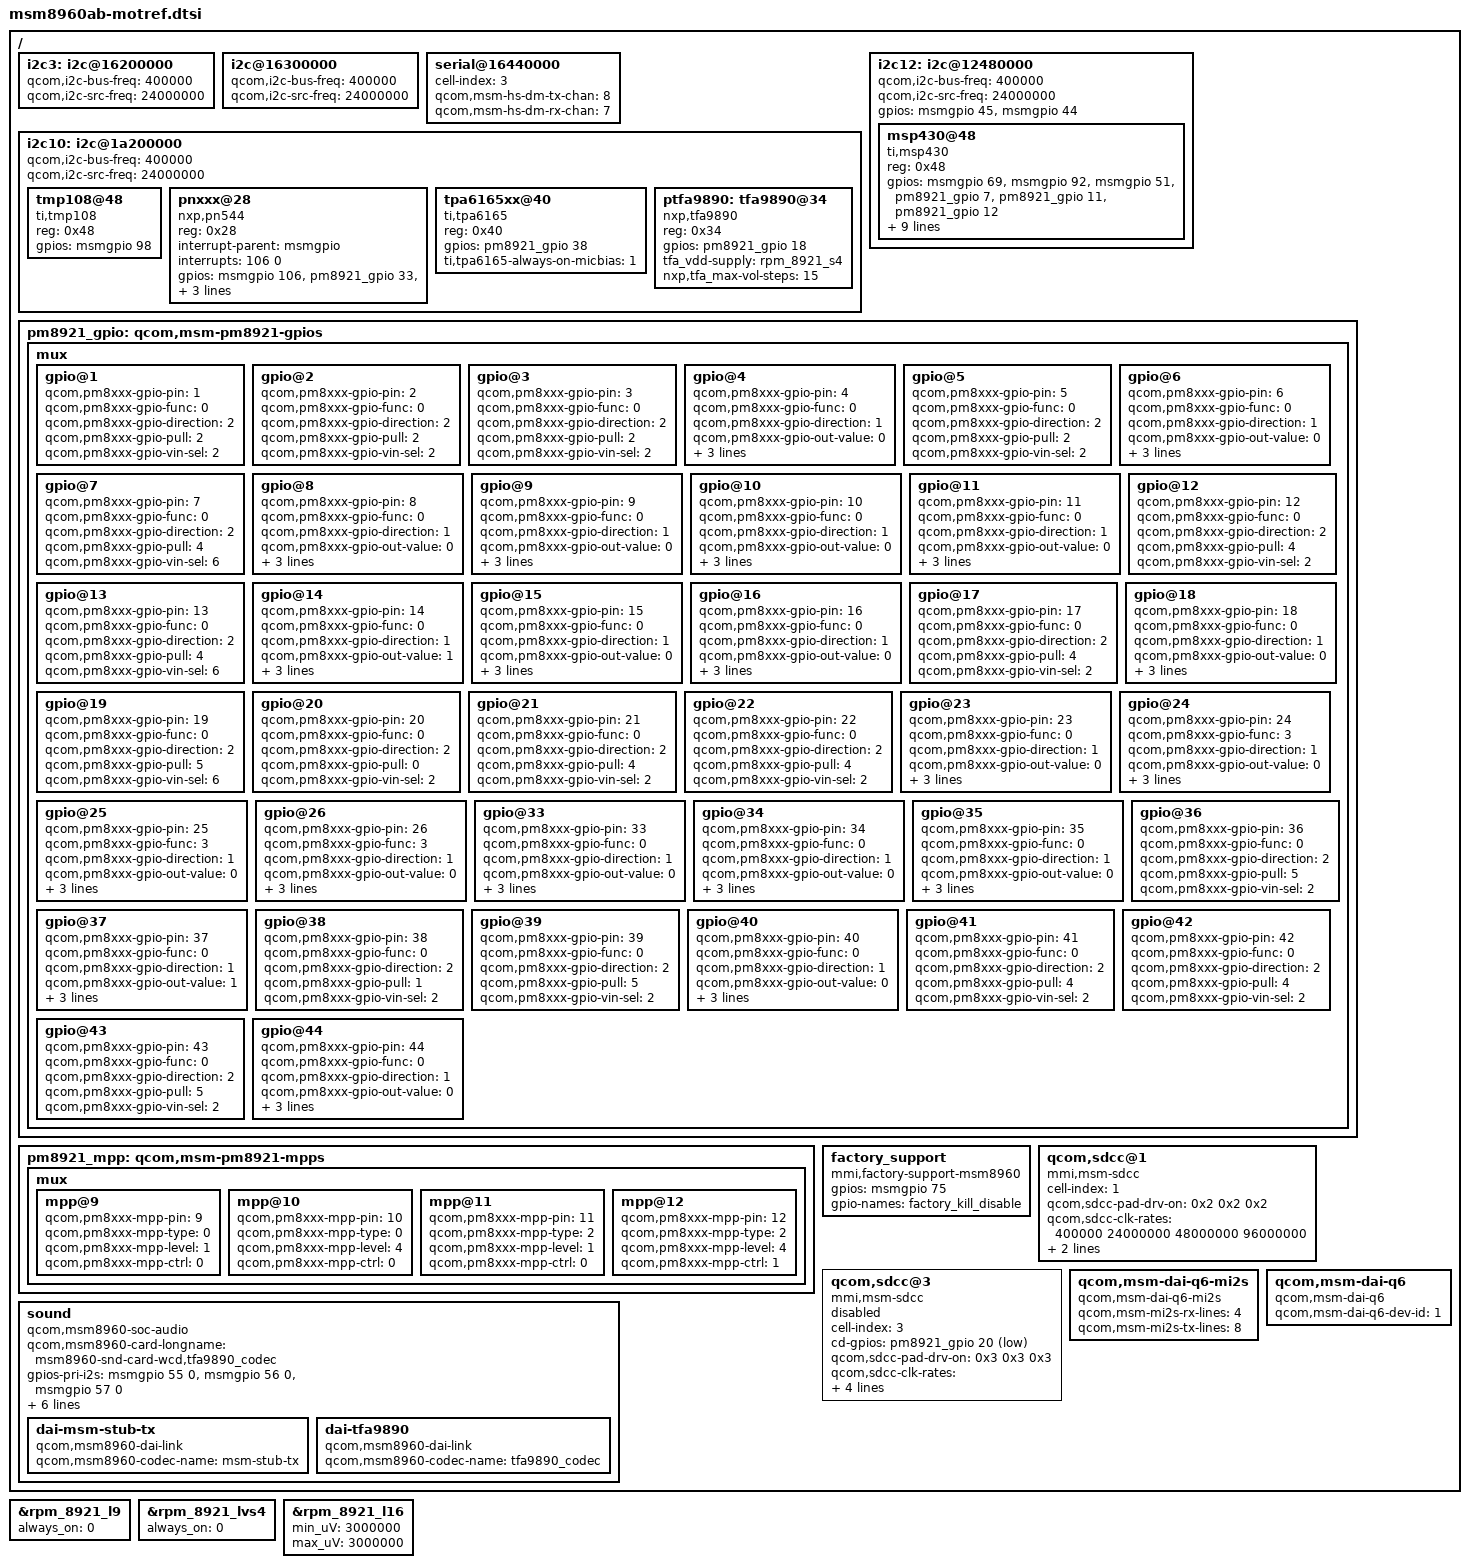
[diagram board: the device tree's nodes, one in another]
/* Common devices of all Motorola msm8960ab reference design based hardware */

/include/ "skeleton.dtsi"
/include/ "msm8960.dtsi"

/include/ "msm8960-motref-pinmux.dtsi"

&rpm_8921_l9 {
	always_on = <0>;
};

&rpm_8921_lvs4 {
	always_on = <0>;
};

&rpm_8921_l16 {
	min_uV = <3000000>;
	max_uV = <3000000>;
};


/ {
	/* GSBI3 - I2C */
	i2c3: i2c@16200000 {
		status = "okay";

		qcom,i2c-bus-freq = <400000>;
		qcom,i2c-src-freq = <24000000>;
	};

	/* GSBI4 - I2C */
	i2c@16300000 {
		status = "okay";

		qcom,i2c-bus-freq = <400000>;
		qcom,i2c-src-freq = <24000000>;
	};

	/* GSBI5 - UART */
	serial@16440000 {
		status = "okay";

		cell-index = <3>;

		qcom,msm-hs-dm-tx-chan = <8>;
		qcom,msm-hs-dm-rx-chan = <7>;
	};

	/* GSBI10 - I2C */
	i2c10: i2c@1a200000 {
		status = "okay";

		qcom,i2c-bus-freq = <400000>;
		qcom,i2c-src-freq = <24000000>;

		tmp108@48 {
			compatible = "ti,tmp108";
			reg = <0x48>;
			gpios = <&msmgpio 98 0>;
		};

		pnxxx@28 {
			compatible = "nxp,pn544";
			reg = <0x28>;
			interrupt-parent = <&msmgpio>;
			interrupts = <106 0>;
			gpios = <&msmgpio 106 0>,     /* IRQ */
				<&pm8921_gpio 33 0>,  /* VEN */
				<&pm8921_gpio 16 0>;  /* Firmware */

			nxp,pnxxx-discharge-delay = <2000>;
			nxp,pnxxx-ven-inv-polarity = <0>;
		};

		tpa6165xx@40 {
			compatible = "ti,tpa6165";
			reg = <0x40>;
			gpios = <&pm8921_gpio 38 0>;     /* IRQ */
			ti,tpa6165-always-on-micbias = <1>;
		};

		ptfa9890: tfa9890@34 {
			compatible = "nxp,tfa9890";
			reg = <0x34>;
			gpios = <&pm8921_gpio 18 0>;     /* RESET */
			tfa_vdd-supply = <&rpm_8921_s4>;
			nxp,tfa_max-vol-steps = <15>;
		};
	};

	/* GSBI12 - I2C */
	i2c12: i2c@12480000 {
		status = "okay";

		qcom,i2c-bus-freq = <400000>;
		qcom,i2c-src-freq = <24000000>;

		gpios = <&msmgpio 45 0>,            /* CLK */
			<&msmgpio 44 0>;            /* DAT */

		msp430@48 {
			compatible = "ti,msp430";
			reg = <0x48>;
			gpios = <&msmgpio 69 0>,     /* IRQ */
				<&msmgpio 92 0>,     /* RESET */
				<&msmgpio 51 0>,     /* BSLEN */
				<&pm8921_gpio 7 0>,  /* WakeIRQ */
				<&pm8921_gpio 11 0>, /* MIPI_REQ */
				<&pm8921_gpio 12 0>; /* MIPI_BUSY */
			lux_table = <5 50 100 1500 3000 8000>;
			brightness_table = <8 13 17 42 61 84 140>;
			bslen_pin_active_value = <1>;
			ct406_detect_threshold = <0x006E>;
			ct406_undetect_threshold = <0x0050>;
			ct406_recalibrate_threshold = <0x0064>;
			ct406_pulse_count = <0x04>;
			vio-supply = <&rpm_8921_lvs4>;
			vcc-supply = <&rpm_8921_l9>;
		};
	};

	pm8921_gpio: qcom,msm-pm8921-gpios {
		mux {
			status = "okay";

			/* KYPD_SNS1 */
			gpio@1 {
				qcom,pm8xxx-gpio-pin = <1>;

				/*
				 * Function    : Normal
				 * Direction   : Input
				 * Pull        : PullUp 31P5
				 * VIN Select  : S4
				 */
				qcom,pm8xxx-gpio-func = <0>;
				qcom,pm8xxx-gpio-direction = <2>;
				qcom,pm8xxx-gpio-pull = <2>;
				qcom,pm8xxx-gpio-vin-sel = <2>;
			};

			/* KYPD_SNS2 */
			gpio@2 {
				qcom,pm8xxx-gpio-pin = <2>;

				/*
				 * Function    : Normal
				 * Direction   : Input
				 * Pull        : PullUp 31P5
				 * VIN Select  : S4
				 */
				qcom,pm8xxx-gpio-func = <0>;
				qcom,pm8xxx-gpio-direction = <2>;
				qcom,pm8xxx-gpio-pull = <2>;
				qcom,pm8xxx-gpio-vin-sel = <2>;
			};

			/* KYPD_SNS3 */
			gpio@3 {
				qcom,pm8xxx-gpio-pin = <3>;

				/*
				 * Function    : Normal
				 * Direction   : Input
				 * Pull        : PullUp 31P5
				 * VIN Select  : S4
				 */
				qcom,pm8xxx-gpio-func = <0>;
				qcom,pm8xxx-gpio-direction = <2>;
				qcom,pm8xxx-gpio-pull = <2>;
				qcom,pm8xxx-gpio-vin-sel = <2>;
			};

			/* TOUCH_R_REQ */
			gpio@4 {
				qcom,pm8xxx-gpio-pin = <4>;

				/*
				 * Function    : Normal
				 * Direction   : Output
				 * Output Val  : Low
				 * Out Strngth : High
				 * Pull        : None
				 * VIN Select  : L17
				*/
				qcom,pm8xxx-gpio-func = <0>;
				qcom,pm8xxx-gpio-direction = <1>;
				qcom,pm8xxx-gpio-out-value = <0>;
				qcom,pm8xxx-gpio-out-strength = <1>;
				qcom,pm8xxx-gpio-pull = <5>;
				qcom,pm8xxx-gpio-vin-sel = <6>;
			};

			/* KYPD_SNS5 */
			gpio@5 {
				qcom,pm8xxx-gpio-pin = <5>;

				/*
				 * Function    : Normal
				 * Direction   : Input
				 * Pull        : PullUp 31P5
				 * VIN Select  : S4
				 */
				qcom,pm8xxx-gpio-func = <0>;
				qcom,pm8xxx-gpio-direction = <2>;
				qcom,pm8xxx-gpio-pull = <2>;
				qcom,pm8xxx-gpio-vin-sel = <2>;
			};

			/* CAM_F_SEL */
			gpio@6 {
				qcom,pm8xxx-gpio-pin = <6>;

				/*
				 * Function    : Normal
				 * Direction   : Output
				 * Output Val  : Low
				 * Out Strngth : High
				 * Pull        : None
				 * VIN Select  : S4
				*/
				qcom,pm8xxx-gpio-func = <0>;
				qcom,pm8xxx-gpio-direction = <1>;
				qcom,pm8xxx-gpio-out-value = <0>;
				qcom,pm8xxx-gpio-out-strength = <1>;
				qcom,pm8xxx-gpio-pull = <5>;
				qcom,pm8xxx-gpio-vin-sel = <2>;
			};

			/* MSP_MSM_INT2 */
			gpio@7 {
				qcom,pm8xxx-gpio-pin = <7>;

				/*
				 * Function    : Normal
				 * Direction   : Input
				 * Pull        : PullDown
				 * VIN Select  : L17
				 */
				qcom,pm8xxx-gpio-func = <0>;
				qcom,pm8xxx-gpio-direction = <2>;
				qcom,pm8xxx-gpio-pull = <4>;
				qcom,pm8xxx-gpio-vin-sel = <6>;
			};

			/* AUD_MCLK_SEL */
			gpio@8 {
				qcom,pm8xxx-gpio-pin = <8>;

				/*
				 * Function    : Normal
				 * Direction   : Output
				 * Output Val  : Low
				 * Out Strngth : High
				 * Pull        : None
				 * VIN Select  : S4
				*/
				qcom,pm8xxx-gpio-func = <0>;
				qcom,pm8xxx-gpio-direction = <1>;
				qcom,pm8xxx-gpio-out-value = <0>;
				qcom,pm8xxx-gpio-out-strength = <1>;
				qcom,pm8xxx-gpio-pull = <5>;
				qcom,pm8xxx-gpio-vin-sel = <2>;
			};

			/* CAM_R_DIG_EN */
			gpio@9 {
				qcom,pm8xxx-gpio-pin = <9>;

				/*
				 * Function    : Normal
				 * Direction   : Output
				 * Output Val  : Low
				 * Out Strngth : High
				 * Pull        : None
				 * VIN Select  : S4
				*/
				qcom,pm8xxx-gpio-func = <0>;
				qcom,pm8xxx-gpio-direction = <1>;
				qcom,pm8xxx-gpio-out-value = <0>;
				qcom,pm8xxx-gpio-out-strength = <1>;
				qcom,pm8xxx-gpio-pull = <5>;
				qcom,pm8xxx-gpio-vin-sel = <2>;
			};

			/* MIPI_D0_SEL */
			gpio@10 {
				qcom,pm8xxx-gpio-pin = <10>;

				/*
				 * Function    : Normal
				 * Direction   : Output
				 * Output Val  : Low
				 * Out Strngth : High
				 * Pull        : None
				 * VIN Select  : S4
				*/
				qcom,pm8xxx-gpio-func = <0>;
				qcom,pm8xxx-gpio-direction = <1>;
				qcom,pm8xxx-gpio-out-value = <0>;
				qcom,pm8xxx-gpio-out-strength = <1>;
				qcom,pm8xxx-gpio-pull = <5>;
				qcom,pm8xxx-gpio-vin-sel = <2>;
			};

			/* MIPI_D0_REQ */
			gpio@11 {
				qcom,pm8xxx-gpio-pin = <11>;

				/*
				 * Function    : Normal
				 * Direction   : Output
				 * Output Val  : Low
				 * Out Strngth : High
				 * Pull        : None
				 * VIN Select  : S4
				*/
				qcom,pm8xxx-gpio-func = <0>;
				qcom,pm8xxx-gpio-direction = <1>;
				qcom,pm8xxx-gpio-out-value = <0>;
				qcom,pm8xxx-gpio-out-strength = <1>;
				qcom,pm8xxx-gpio-pull = <5>;
				qcom,pm8xxx-gpio-vin-sel = <2>;
			};

			/* MIPI_D0_BUSY */
			gpio@12 {
				qcom,pm8xxx-gpio-pin = <12>;

				/*
				 * Function    : Normal
				 * Direction   : Input
				 * Pull        : PullDown
				 * VIN Select  : S4
				 */
				qcom,pm8xxx-gpio-func = <0>;
				qcom,pm8xxx-gpio-direction = <2>;
				qcom,pm8xxx-gpio-pull = <4>;
				qcom,pm8xxx-gpio-vin-sel = <2>;
			};

			/* TOUCH_R_BUSY */
			gpio@13 {
				qcom,pm8xxx-gpio-pin = <13>;

				/*
				 * Function    : Normal
				 * Direction   : Input
				 * Pull        : PullDown
				 * VIN Select  : L17
				 */
				qcom,pm8xxx-gpio-func = <0>;
				qcom,pm8xxx-gpio-direction = <2>;
				qcom,pm8xxx-gpio-pull = <4>;
				qcom,pm8xxx-gpio-vin-sel = <6>;
			};

			/* C55_CORE_EN */
			gpio@14 {
				qcom,pm8xxx-gpio-pin = <14>;

				/*
				 * Function    : Normal
				 * Direction   : Output
				 * Output Val  : High
				 * Out Strngth : High
				 * Pull        : None
				 * VIN Select  : S4
				*/
				qcom,pm8xxx-gpio-func = <0>;
				qcom,pm8xxx-gpio-direction = <1>;
				qcom,pm8xxx-gpio-out-value = <1>;
				qcom,pm8xxx-gpio-out-strength = <1>;
				qcom,pm8xxx-gpio-pull = <5>;
				qcom,pm8xxx-gpio-vin-sel = <2>;
			};

			/* C55_RST_N */
			gpio@15 {
				qcom,pm8xxx-gpio-pin = <15>;

				/*
				 * Function    : Normal
				 * Direction   : Output
				 * Output Val  : Low
				 * Out Strngth : High
				 * Pull        : None
				 * VIN Select  : S4
				*/
				qcom,pm8xxx-gpio-func = <0>;
				qcom,pm8xxx-gpio-direction = <1>;
				qcom,pm8xxx-gpio-out-value = <0>;
				qcom,pm8xxx-gpio-out-strength = <1>;
				qcom,pm8xxx-gpio-pull = <5>;
				qcom,pm8xxx-gpio-vin-sel = <2>;
			};

			/* NFC_FW_UPDATE */
			gpio@16 {
				qcom,pm8xxx-gpio-pin = <16>;

				/*
				 * Function    : Normal
				 * Direction   : Output
				 * Output Val  : Low
				 * Out Strngth : High
				 * Pull        : None
				 * VIN Select  : S4
				*/
				qcom,pm8xxx-gpio-func = <0>;
				qcom,pm8xxx-gpio-direction = <1>;
				qcom,pm8xxx-gpio-out-value = <0>;
				qcom,pm8xxx-gpio-out-strength = <1>;
				qcom,pm8xxx-gpio-pull = <5>;
				qcom,pm8xxx-gpio-vin-sel = <2>;
			};

			/* UNUSUED - INPUT, PULLDOWN */
			gpio@17 {
				qcom,pm8xxx-gpio-pin = <17>;

				/*
				 * Function    : Normal
				 * Direction   : Input
				 * Pull        : PullDown
				 * VIN Select  : S4
				 */
				qcom,pm8xxx-gpio-func = <0>;
				qcom,pm8xxx-gpio-direction = <2>;
				qcom,pm8xxx-gpio-pull = <4>;
				qcom,pm8xxx-gpio-vin-sel = <2>;
			};

			/* AUD_AIC_RST_N */
			gpio@18 {
				qcom,pm8xxx-gpio-pin = <18>;

				/*
				 * Function    : Normal
				 * Direction   : Output
				 * Output Val  : Low
				 * Out Strngth : High
				 * Pull        : None
				 * VIN Select  : S4
				*/
				qcom,pm8xxx-gpio-func = <0>;
				qcom,pm8xxx-gpio-direction = <1>;
				qcom,pm8xxx-gpio-out-value = <0>;
				qcom,pm8xxx-gpio-out-strength = <1>;
				qcom,pm8xxx-gpio-pull = <5>;
				qcom,pm8xxx-gpio-vin-sel = <2>;
			};

			/* ID_FLOAT */
			gpio@19 {
				qcom,pm8xxx-gpio-pin = <19>;

				/*
				 * Function    : Normal
				 * Direction   : Input
				 * Pull        : None
				 * VIN Select  : L17
				 */
				qcom,pm8xxx-gpio-func = <0>;
				qcom,pm8xxx-gpio-direction = <2>;
				qcom,pm8xxx-gpio-pull = <5>;
				qcom,pm8xxx-gpio-vin-sel = <6>;
			};

			/* SD_DET_N */
			gpio@20 {
				qcom,pm8xxx-gpio-pin = <20>;

				/*
				 * Function    : Normal
				 * Direction   : Input
				 * Pull        : PullUp 30
				 * VIN Select  : S4
				 */
				qcom,pm8xxx-gpio-func = <0>;
				qcom,pm8xxx-gpio-direction = <2>;
				qcom,pm8xxx-gpio-pull = <0>;
				qcom,pm8xxx-gpio-vin-sel = <2>;
			};

			/* UNUSUED - INPUT, PULLDOWN */
			gpio@21 {
				qcom,pm8xxx-gpio-pin = <21>;

				/*
				 * Function    : Normal
				 * Direction   : Input
				 * Pull        : PullDown
				 * VIN Select  : S4
				 */
				qcom,pm8xxx-gpio-func = <0>;
				qcom,pm8xxx-gpio-direction = <2>;
				qcom,pm8xxx-gpio-pull = <4>;
				qcom,pm8xxx-gpio-vin-sel = <2>;
			};

			/* UNUSUED - INPUT, PULLDOWN */
			gpio@22 {
				qcom,pm8xxx-gpio-pin = <22>;

				/*
				 * Function    : Normal
				 * Direction   : Input
				 * Pull        : PullDown
				 * VIN Select  : S4
				 */
				qcom,pm8xxx-gpio-func = <0>;
				qcom,pm8xxx-gpio-direction = <2>;
				qcom,pm8xxx-gpio-pull = <4>;
				qcom,pm8xxx-gpio-vin-sel = <2>;
			};

			/* EXT_VREG_S3_VSEL */
			gpio@23 {
				qcom,pm8xxx-gpio-pin = <23>;

				/*
				 * Function    : Normal
				 * Direction   : Output
				 * Output Val  : Low
				 * Out Strngth : High
				 * Pull        : None
				 * VIN Select  : S4
				*/
				qcom,pm8xxx-gpio-func = <0>;
				qcom,pm8xxx-gpio-direction = <1>;
				qcom,pm8xxx-gpio-out-value = <0>;
				qcom,pm8xxx-gpio-out-strength = <1>;
				qcom,pm8xxx-gpio-pull = <5>;
				qcom,pm8xxx-gpio-vin-sel = <2>;
			};

			/* RED_LED_SINK */
			gpio@24 {
				qcom,pm8xxx-gpio-pin = <24>;

				/*
				 * Function    : FUNC_2
				 * Direction   : Output
				 * Output Val  : Low
				 * Out Strngth : High
				 * Pull        : None
				 * VIN Select  : S4
				*/
				qcom,pm8xxx-gpio-func = <3>;
				qcom,pm8xxx-gpio-direction = <1>;
				qcom,pm8xxx-gpio-out-value = <0>;
				qcom,pm8xxx-gpio-out-strength = <1>;
				qcom,pm8xxx-gpio-pull = <5>;
				qcom,pm8xxx-gpio-vin-sel = <2>;
			};

			/* GREEN_LED_SINK */
			gpio@25 {
				qcom,pm8xxx-gpio-pin = <25>;

				/*
				 * Function    : FUNC_2
				 * Direction   : Output
				 * Output Val  : Low
				 * Out Strngth : High
				 * Pull        : None
				 * VIN Select  : S4
				*/
				qcom,pm8xxx-gpio-func = <3>;
				qcom,pm8xxx-gpio-direction = <1>;
				qcom,pm8xxx-gpio-out-value = <0>;
				qcom,pm8xxx-gpio-out-strength = <1>;
				qcom,pm8xxx-gpio-pull = <5>;
				qcom,pm8xxx-gpio-vin-sel = <2>;
			};

			/* BLUE_LED_SINK */
			gpio@26 {
				qcom,pm8xxx-gpio-pin = <26>;

				/*
				 * Function    : FUNC_2
				 * Direction   : Output
				 * Output Val  : Low
				 * Out Strngth : High
				 * Pull        : None
				 * VIN Select  : S4
				*/
				qcom,pm8xxx-gpio-func = <3>;
				qcom,pm8xxx-gpio-direction = <1>;
				qcom,pm8xxx-gpio-out-value = <0>;
				qcom,pm8xxx-gpio-out-strength = <1>;
				qcom,pm8xxx-gpio-pull = <5>;
				qcom,pm8xxx-gpio-vin-sel = <2>;
			};

			/* NFC_ENABLE */
			gpio@33 {
				qcom,pm8xxx-gpio-pin = <33>;

				/*
				 * Function    : Normal
				 * Direction   : Output
				 * Output Val  : Low
				 * Out Strngth : High
				 * Pull        : None
				 * VIN Select  : S4
				*/
				qcom,pm8xxx-gpio-func = <0>;
				qcom,pm8xxx-gpio-direction = <1>;
				qcom,pm8xxx-gpio-out-value = <0>;
				qcom,pm8xxx-gpio-out-strength = <1>;
				qcom,pm8xxx-gpio-pull = <5>;
				qcom,pm8xxx-gpio-vin-sel = <2>;
			};

			/* WCD9310_RESET_N */
			gpio@34 {
				qcom,pm8xxx-gpio-pin = <34>;

				/*
				 * Function    : Normal
				 * Direction   : Output
				 * Output Val  : Low
				 * Out Strngth : High
				 * Pull        : None
				 * VIN Select  : S4
				*/
				qcom,pm8xxx-gpio-func = <0>;
				qcom,pm8xxx-gpio-direction = <1>;
				qcom,pm8xxx-gpio-out-value = <0>;
				qcom,pm8xxx-gpio-out-strength = <1>;
				qcom,pm8xxx-gpio-pull = <5>;
				qcom,pm8xxx-gpio-vin-sel = <2>;
			};

			/* EXT_VREG_S3_EN */
			gpio@35 {
				qcom,pm8xxx-gpio-pin = <35>;

				/*
				 * Function    : Normal
				 * Direction   : Output
				 * Output Val  : Low
				 * Out Strngth : High
				 * Pull        : None
				 * VIN Select  : S4
				*/
				qcom,pm8xxx-gpio-func = <0>;
				qcom,pm8xxx-gpio-direction = <1>;
				qcom,pm8xxx-gpio-out-value = <0>;
				qcom,pm8xxx-gpio-out-strength = <1>;
				qcom,pm8xxx-gpio-pull = <5>;
				qcom,pm8xxx-gpio-vin-sel = <2>;
			};

			/* SIM_DET */
			gpio@36 {
				qcom,pm8xxx-gpio-pin = <36>;

				/*
				 * Function    : Normal
				 * Direction   : Input
				 * Pull        : None
				 * VIN Select  : S4
				 */
				qcom,pm8xxx-gpio-func = <0>;
				qcom,pm8xxx-gpio-direction = <2>;
				qcom,pm8xxx-gpio-pull = <5>;
				qcom,pm8xxx-gpio-vin-sel = <2>;
			};

			/* DISP_RST_N */
			gpio@37 {
				qcom,pm8xxx-gpio-pin = <37>;

				/*
				 * Function    : Normal
				 * Direction   : Output
				 * Output Val  : High
				 * Out Strngth : High
				 * Pull        : None
				 * VIN Select  : S4
				*/
				qcom,pm8xxx-gpio-func = <0>;
				qcom,pm8xxx-gpio-direction = <1>;
				qcom,pm8xxx-gpio-out-value = <1>;
				qcom,pm8xxx-gpio-out-strength = <1>;
				qcom,pm8xxx-gpio-pull = <5>;
				qcom,pm8xxx-gpio-vin-sel = <2>;
			};

			/* HEADSET_INT */
			gpio@38 {
				qcom,pm8xxx-gpio-pin = <38>;

				/*
				 * Function    : Normal
				 * Direction   : Input
				 * Pull        : PullUp 1P5
				 * VIN Select  : S4
				 */
				qcom,pm8xxx-gpio-func = <0>;
				qcom,pm8xxx-gpio-direction = <2>;
				qcom,pm8xxx-gpio-pull = <1>;
				qcom,pm8xxx-gpio-vin-sel = <2>;
			};

			/* CLK_MSM_FWD */
			gpio@39 {
				qcom,pm8xxx-gpio-pin = <39>;

				/*
				 * Function    : Normal
				 * Direction   : Input
				 * Pull        : None
				 * VIN Select  : S4
				 */
				qcom,pm8xxx-gpio-func = <0>;
				qcom,pm8xxx-gpio-direction = <2>;
				qcom,pm8xxx-gpio-pull = <5>;
				qcom,pm8xxx-gpio-vin-sel = <2>;
			};

			/* OTG_OVP_CNTL */
			gpio@40 {
				qcom,pm8xxx-gpio-pin = <40>;

				/*
				 * Function    : Normal
				 * Direction   : Output
				 * Output Val  : Low
				 * Out Strngth : High
				 * Pull        : None
				 * VIN Select  : S4
				*/
				qcom,pm8xxx-gpio-func = <0>;
				qcom,pm8xxx-gpio-direction = <1>;
				qcom,pm8xxx-gpio-out-value = <0>;
				qcom,pm8xxx-gpio-out-strength = <1>;
				qcom,pm8xxx-gpio-pull = <5>;
				qcom,pm8xxx-gpio-vin-sel = <2>;
			};

			/* UNUSUED - INPUT, PULLDOWN */
			gpio@41 {
				qcom,pm8xxx-gpio-pin = <41>;

				/*
				 * Function    : Normal
				 * Direction   : Input
				 * Pull        : PullDown
				 * VIN Select  : S4
				 */
				qcom,pm8xxx-gpio-func = <0>;
				qcom,pm8xxx-gpio-direction = <2>;
				qcom,pm8xxx-gpio-pull = <4>;
				qcom,pm8xxx-gpio-vin-sel = <2>;
			};

			/* UNUSUED - INPUT, PULLDOWN */
			gpio@42 {
				qcom,pm8xxx-gpio-pin = <42>;

				/*
				 * Function    : Normal
				 * Direction   : Input
				 * Pull        : PullDown
				 * VIN Select  : S4
				 */
				qcom,pm8xxx-gpio-func = <0>;
				qcom,pm8xxx-gpio-direction = <2>;
				qcom,pm8xxx-gpio-pull = <4>;
				qcom,pm8xxx-gpio-vin-sel = <2>;
			};

			/* OTG_OC_FLAG_N */
			gpio@43 {
				qcom,pm8xxx-gpio-pin = <43>;

				/*
				 * Function    : Normal
				 * Direction   : Input
				 * Pull        : None
				 * VIN Select  : S4
				 */
				qcom,pm8xxx-gpio-func = <0>;
				qcom,pm8xxx-gpio-direction = <2>;
				qcom,pm8xxx-gpio-pull = <5>;
				qcom,pm8xxx-gpio-vin-sel = <2>;
			};

			/* SPKR_RIGHT_EN */
			gpio@44 {
				qcom,pm8xxx-gpio-pin = <44>;

				/*
				 * Function    : Normal
				 * Direction   : Output
				 * Output Val  : Low
				 * Out Strngth : High
				 * Pull        : None
				 * VIN Select  : S4
				*/
				qcom,pm8xxx-gpio-func = <0>;
				qcom,pm8xxx-gpio-direction = <1>;
				qcom,pm8xxx-gpio-out-value = <0>;
				qcom,pm8xxx-gpio-out-strength = <1>;
				qcom,pm8xxx-gpio-pull = <5>;
				qcom,pm8xxx-gpio-vin-sel = <2>;
			};
		};
	};

	/* PM8921 - MPP */
	pm8921_mpp: qcom,msm-pm8921-mpps {
		mux {
			status = "okay";

			mpp@9 {
				/* ADC_MCLK_EN */
				qcom,pm8xxx-mpp-pin = <9>;

				/*
				 * type   : D_INPUT
				 * level  : S4
				 * control: DIN_TO_INT
				 */
				qcom,pm8xxx-mpp-type = <0>;
				qcom,pm8xxx-mpp-level = <1>;
				qcom,pm8xxx-mpp-ctrl = <0>;
			};

			mpp@10 {
				/* ID_GND */
				qcom,pm8xxx-mpp-pin = <10>;

				/*
				 * type   : D_INPUT
				 * level  : L17
				 * control: DIN_TO_INT
				 */
				qcom,pm8xxx-mpp-type = <0>;
				qcom,pm8xxx-mpp-level = <4>;
				qcom,pm8xxx-mpp-ctrl = <0>;
			};

			mpp@11 {
				/* BATT_ID_MSM */
				qcom,pm8xxx-mpp-pin = <11>;

				/*
				 * type   : D_BI_DIR
				 * level  : S4
				 * control: PULLUP_1KOHM
				 */
				qcom,pm8xxx-mpp-type = <2>;
				qcom,pm8xxx-mpp-level = <1>;
				qcom,pm8xxx-mpp-ctrl = <0>;
			};

			mpp@12 {
				/* BATT_ID */
				qcom,pm8xxx-mpp-pin = <12>;

				/*
				 * type   : D_BI_DIR
				 * level  : L17
				 * control: PULLUP_OPEN
				 */
				qcom,pm8xxx-mpp-type = <2>;
				qcom,pm8xxx-mpp-level = <4>;
				qcom,pm8xxx-mpp-ctrl = <1>;
			};
		};
	};

	factory_support {
		compatible = "mmi,factory-support-msm8960";

		gpios = <&msmgpio 75 0x2>; /* GPIOF_DIR_OUT | GPIOF_INIT_HIGH */
		gpio-names = "factory_kill_disable";
	};

	/* SDCC */
	qcom,sdcc@1 {
		cell-index = <1>; /* SDC1 eMMC slot */
		compatible = "mmi,msm-sdcc";

		qcom,sdcc-pad-drv-on = <0x2 0x2 0x2>; /* 6mA, 6mA, 6mA */

		qcom,sdcc-clk-rates = <400000 24000000 48000000 96000000>;
		qcom,sdcc-bus-speed-mode = "HS200_1p8v", "DDR_1p8v";
		qcom,sdcc-max-power-class = <6>;
	};

	qcom,sdcc@3 {
		cell-index = <3>; /* SDC3 SD card slot */
		compatible = "mmi,msm-sdcc";
		cd-gpios = <&pm8921_gpio 20 0x1>;
		status = "disabled";

		qcom,sdcc-pad-drv-on = <0x3 0x3 0x3>; /* 8mA, 8mA, 8mA */

		qcom,sdcc-clk-rates = <400000 24000000 48000000 96000000 192000000>;
		qcom,sdcc-bus-speed-mode = "SDR12", "SDR25", "SDR50", "DDR50";
		qcom,sdcc-current-limit = <600>;
	};

	sound {
		status = "okay";
		compatible = "qcom,msm8960-soc-audio";

		qcom,msm8960-card-longname =
			"msm8960-snd-card-wcd,tfa9890_codec";

		/* Primary I2S GPIOs - c55 path */
		gpios-pri-i2s = <&msmgpio 55 0>, /* SCK */
				<&msmgpio 56 0>, /* WS */
				<&msmgpio 57 0>; /* DIN */
		gpios-pri-i2s-names = "pri-i2s-sck",
				      "pri-i2s-ws",
				      "pri-i2s-din";

		/* MI2S */
		gpios-mi2s = <&msmgpio 47 0>, /* WS   */
			     <&msmgpio 48 0>, /* SCK  */
			     <&msmgpio 49 0>, /* DIN  */
			     <&msmgpio 50 0>, /* DOUT */
			     <&msmgpio 53 0>; /* MCLK */
		gpios-mi2s-names = "mi2s_ws",
				  "mi2s_sck",
				  "mi2s_din",
				  "mi2s_dout",
				  "mi2s_mclk";

		/* DAI Links */
		dai-msm-stub-tx {
			compatible = "qcom,msm8960-dai-link";
			qcom,msm8960-codec-name = "msm-stub-tx";
		};

		dai-tfa9890 {
			compatible = "qcom,msm8960-dai-link";
			qcom,msm8960-codec-name = "tfa9890_codec";
		};
	};

	qcom,msm-dai-q6-mi2s {
		compatible = "qcom,msm-dai-q6-mi2s";
		qcom,msm-mi2s-rx-lines = <4>; /* MSM_MI2S_SD2 */
		qcom,msm-mi2s-tx-lines = <8>; /* MSM_MI2S_SD3 */
	};

	qcom,msm-dai-q6 {
		compatible = "qcom,msm-dai-q6";
		qcom,msm-dai-q6-dev-id = <1>; /* PRIMARY_I2S_TX */
	};

};
